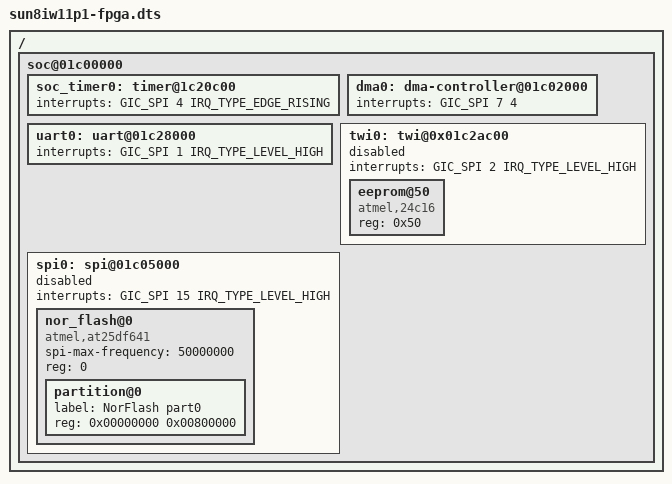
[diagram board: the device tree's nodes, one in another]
/*
 * Allwinner Technology CO., Ltd. sun8iw11p1 fpga board.
 *
 * fpga board support.
 */

/dts-v1/;
#include "sun8iw11p1.dtsi"

/{

	soc@01c00000 {
		soc_timer0: timer@1c20c00 {
			interrupts = <GIC_SPI 4 IRQ_TYPE_EDGE_RISING>;
		};

		dma0:dma-controller@01c02000 {
			interrupts = <GIC_SPI 7 4>;
		};

		uart0: uart@01c28000 {
			interrupts = <GIC_SPI 1 IRQ_TYPE_LEVEL_HIGH>;           /* uart0 is IRQ33 on fpga */
			status = "okay";
		};

		twi0: twi@0x01c2ac00 {
			interrupts = <GIC_SPI 2 IRQ_TYPE_LEVEL_HIGH>;           /* twi0 is IRQ34 on fpga (conflict with gpio) */
			status = "disabled";

			eeprom@50 {
				compatible = "atmel,24c16";
				reg = <0x50>;
			};
		};

		spi0: spi@01c05000 {
			interrupts = <GIC_SPI 15 IRQ_TYPE_LEVEL_HIGH>;          /* spi0 is IRQ47 on fpga */
			status = "disabled";

			nor_flash@0 {
				#address-cells = <1>;
				#size-cells = <1>;
				compatible = "atmel,at25df641";
				spi-max-frequency = <50000000>;
				reg = <0>;	/* Chip select 0 */

				partition@0 {
					label = "NorFlash part0";
					reg = <0x00000000 0x00800000>;
				};
			};
		};
	};
};
